# nrf9230_celldsp register map
Vendor: Nordic Semiconductor; Series: nRF92; File version: 1
Registers are 32-bit, read-write, reset 0x0 unless marked. A register's access mark holds for its fields unless they carry their own. Offsets are from the block's base; [hi:lo] are bit positions; {n}, {i} and the like mark numbered series; 'fields as' and 'values as' point back to an identical list.

## GNSSFE — Position Front End 0
Base 0x45028000
Same registers: WIFIBFE 0x45029000, WIFIGNFE 0x4502A000
0x00 TASKS_STARTRX wo — Start receiving rx samples from RF digital
  [0] TASKS_STARTRX
    1=Trigger task
0x04 TASKS_STOPRX wo — Stop receiving rx samples from RF digital
  [0] TASKS_STOPRX
    1=Trigger task
0x08 TASKS_RESET wo — Reset configuration registers to initial state.
  [0] TASKS_RESET
    1=Trigger task
0x0C TASKS_STARTRXTIMED wo — Start receiving rx samples from RF digital when TBC = RXSTART
  [0] TASKS_STARTRXTIMED
    1=Trigger task
0x100 EVENTS_RXSAMPLEREADY — Programmable number of rx samples received from RF digital
  [0] EVENTS_RXSAMPLEREADY
    0=NotGenerated (Event not generated); 1=Generated (Event generated)
0x104 EVENTS_RXSADDRREADY — Rx samples written to programmable RAM buffer address
  [0] EVENTS_RXSADDRREADY
    values as EVENTS_RXSAMPLEREADY.EVENTS_RXSAMPLEREADY
0x108 EVENTS_RX2SADDRREADY — Rx samples written to programmable secondary RAM buffer address
  [0] EVENTS_RX2SADDRREADY
    values as EVENTS_RXSAMPLEREADY.EVENTS_RXSAMPLEREADY
0x10C EVENTS_RXOVERFLOW — Rx fifo overflow event
  [0] EVENTS_RXOVERFLOW
    values as EVENTS_RXSAMPLEREADY.EVENTS_RXSAMPLEREADY
0x110 EVENTS_RXRESYNCOVERFLOW — Rx Resync fifo overflow event
  [0] EVENTS_RXRESYNCOVERFLOW
    values as EVENTS_RXSAMPLEREADY.EVENTS_RXSAMPLEREADY
0x114 EVENTS_RX2SAMPLEREADY — Programmable number of rx samples received to secondary buffer from RF digital
  [0] EVENTS_RX2SAMPLEREADY
    values as EVENTS_RXSAMPLEREADY.EVENTS_RXSAMPLEREADY
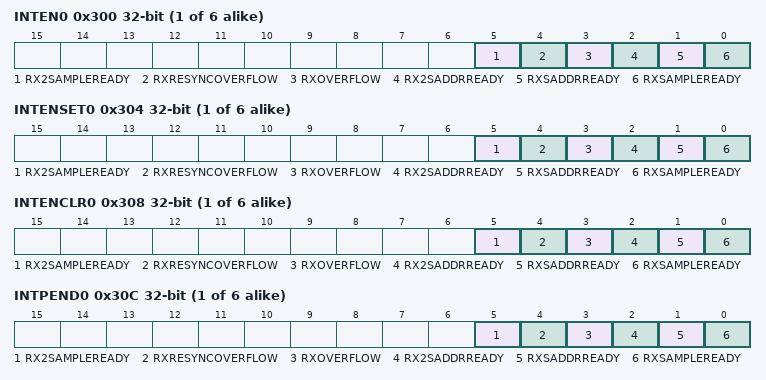
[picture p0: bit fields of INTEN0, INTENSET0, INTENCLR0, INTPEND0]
{0x300+0x10*i} INTEN{i} (i=0..5) — Enable or disable interrupt
  [all] fields
    0=Disabled; 1=Enabled
  [5] RX2SAMPLEREADY — Enable or disable interrupt for event RX2SAMPLEREADY
  [4] RXRESYNCOVERFLOW — Enable or disable interrupt for event RXRESYNCOVERFLOW
  [3] RXOVERFLOW — Enable or disable interrupt for event RXOVERFLOW
  [2] RX2SADDRREADY — Enable or disable interrupt for event RX2SADDRREADY
  [1] RXSADDRREADY — Enable or disable interrupt for event RXSADDRREADY
  [0] RXSAMPLEREADY — Enable or disable interrupt for event RXSAMPLEREADY
{0x304+0x10*i} INTENSET{i} (i=0..5) — Enable interrupt
  [all] fields
    on read: 0=Disabled (Read: Disabled); 1=Enabled (Read: Enabled) | on write: 1=Set (Enable)
  [5] RX2SAMPLEREADY — Write '1' to enable interrupt for event RX2SAMPLEREADY
  [4] RXRESYNCOVERFLOW — Write '1' to enable interrupt for event RXRESYNCOVERFLOW
  [3] RXOVERFLOW — Write '1' to enable interrupt for event RXOVERFLOW
  [2] RX2SADDRREADY — Write '1' to enable interrupt for event RX2SADDRREADY
  [1] RXSADDRREADY — Write '1' to enable interrupt for event RXSADDRREADY
  [0] RXSAMPLEREADY — Write '1' to enable interrupt for event RXSAMPLEREADY
{0x308+0x10*i} INTENCLR{i} (i=0..5) — Disable interrupt
  [all] fields
    on read: 0=Disabled (Read: Disabled); 1=Enabled (Read: Enabled) | on write: 1=Clear (Disable)
  [5] RX2SAMPLEREADY — Write '1' to disable interrupt for event RX2SAMPLEREADY
  [4] RXRESYNCOVERFLOW — Write '1' to disable interrupt for event RXRESYNCOVERFLOW
  [3] RXOVERFLOW — Write '1' to disable interrupt for event RXOVERFLOW
  [2] RX2SADDRREADY — Write '1' to disable interrupt for event RX2SADDRREADY
  [1] RXSADDRREADY — Write '1' to disable interrupt for event RXSADDRREADY
  [0] RXSAMPLEREADY — Write '1' to disable interrupt for event RXSAMPLEREADY
{0x30C+0x10*i} INTPEND{i} ro (i=0..5) — Pending interrupts
  [all] fields
    on read: 0=NotPending (Read: Not pending); 1=Pending (Read: Pending)
  [5] RX2SAMPLEREADY — Read pending status of interrupt for event RX2SAMPLEREADY
  [4] RXRESYNCOVERFLOW — Read pending status of interrupt for event RXRESYNCOVERFLOW
  [3] RXOVERFLOW — Read pending status of interrupt for event RXOVERFLOW
  [2] RX2SADDRREADY — Read pending status of interrupt for event RX2SADDRREADY
  [1] RXSADDRREADY — Read pending status of interrupt for event RXSADDRREADY
  [0] RXSAMPLEREADY — Read pending status of interrupt for event RXSAMPLEREADY
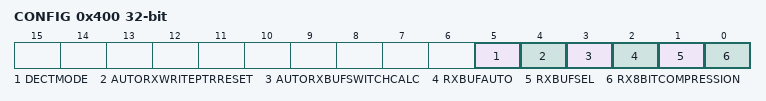
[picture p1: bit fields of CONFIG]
0x400 CONFIG — POSFE configuration register
  [5] DECTMODE — DECT mode selection for interfacing to DECTSYNC HW for non-DECT signal receiving
    0=Disabled (DECT mode disabled); 1=Enabled (DECT mode enabled)
  [4] AUTORXWRITEPTRRESET — Automatic Rx write pointer reset in AHB FSM
    0=Disabled (Autoreset disabled); 1=Enabled (Autoreset enabled)
  [3] AUTORXBUFSWITCHCALC — Automatic Rx buffer switchpoint calculation
    0=Disabled (Autocalculation disabled); 1=Enabled (Autocalculation enabled)
  [2] RXBUFAUTO — Automatic rx buffer switching mode
    0=Disabled (Automatic mode disabled); 1=Enabled (Automatic mode enabled)
  [1] RXBUFSEL — Manual rx buffer switching mode. In automatic mode defines also which buffer will be filled first
    0=Main rx buffer selected; 1=Secondary rx buffer selected
  [0] RX8BITCOMPRESSION — RX output format selector
    0=Sixteen (Each sample, I or Q, in output data is 16 bits); 1=Eight (Each sample, I or Q, in output data is 8 bits)
0x404 TBCINITVALUELO — Lower 32 bits of TimeBaseCounter initialization value
  [31:0] TBCINITLO — TBC Initialization
0x408 TBCINITVALUEHI — Higher 32 bits of TimeBaseCounter initialization value
  [31:0] TBCINITHI — TBC Initialization
0x40C TBCRXENDLO — Lower 32 bits of Rx End time
  [31:0] RXENDLO — TBC count to disable RX
0x410 TBCRXENDHI — Higher 32 bits of Rx End time
  [31:0] RXENDHI — TBC count to disable RX
0x414 RXBUFSWITCHLO — Lower 32 bits of TBC value to switch to another RAM buffer
  [31:0] RX2SWITCHLO — Switch point to secondary Rx buffer
0x418 RXBUFSWITCHHI — Higher 32 bits of TBC value to switch to another RAM buffer
  [31:0] RX2SWITCHI — Switch point to secondary Rx buffer
0x41C RXSAMPLEINTTRIG — Rx sample interrupt trigger value. Number of samples received from RF digital.
  [15:0] RXSAMPLEINTTRIG — Rx sample interrupt trigger
0x420 RXSADDRINTTRIG — Rx sample interrupt trigger value. RAM address where samples written.
  [31:0] RXSADDRINTTRIG — Rx sample interrupt trigger.
0x424 RX2SADDRINTTRIG — Rx 2 sample interrupt trigger value. RAM address where samples written.
  [31:0] RX2SADDRINTTRIG — Rx 2 sample interrupt trigger
0x428 RXDMABASEADDR — Rx write base address to RAM memory
  [31:0] RXDMABASEADDR — Rx buffer base address
0x42C RXDMABUFFERSIZE — Rx RAM buffer size
  [31:0] RXDMABUFFERSIZE — Rx buffer size
0x430 RXDMAWRITEPTR — Rx write pointer to RAM memory
  [31:0] RXDMAWRITEPTR — Rx buffer write pointer
0x434 RX2DMABASEADDR — Rx 2 write base address to RAM memory
  [31:0] RX2DMABASEADDR — Rx buffer 2 base address
0x438 RX2DMABUFFERSIZE — Rx 2 RAM buffer size
  [31:0] RX2DMABUFFERSIZE — Rx buffer 2 size
0x43C RX2DMAWRITEPTR — Rx 2 write pointer to RAM memory
  [31:0] RX2DMAWRITEPTR — Rx buffer 2 write pointer
0x440 PATHSTATUS ro
  [0] RXPATH — RX path status
    0=TaskInactive (Rx task not activated); 1=TaskActive (Rx task ongoing)
0x444 RX2SAMPLEINTTRIG — Rx secondary buffer sample interrupt trigger value. Number of samples received from RF digital.
  [15:0] RX2SAMPLEINTTRIG — Rx 2 sample interrupt trigger
0x448 RXSAMPLECOUNTER ro — Rx sample counter value
  [15:0] RXSAMPLECNTR
0x44C RXSLOTSIZELO — Lower 32 bits of Rx slot size in automatic buffer switching
  [31:0] RXSLOTLO — Rx slot size
0x450 RXSLOTSIZEHI — Higher 32 bits of Rx slot size in automatic buffer switching
  [31:0] RXSLOTHI — Rx slot size
0x454 RXSTARTLO — Lower 32 bits of Rx start time in timed rx mode
  [31:0] RXSTARTLO — TBC count to start Rx
0x458 RXSTARTHI — Higher 32 bits of Rx start time in timed rx mode
  [31:0] RXSTARTHI — TBC count to start Rx
0x45C RXSTOPLO — Lower 32 bits of Rx stop time in timed rx mode
  [31:0] RXSTOPLO — TBC count to stop Rx
0x460 RXSTOPHI — Higher 32 bits of Rx stop time in timed rx mode
  [31:0] RXSTOPHI — TBC count to stop Rx
0x464 RXROUNDCONSTPOS reset 0xFF — Rounding constant for 8bit output format
  [15:0] RXROUNDCONSTPOS — Constant for positive input values
0x468 RXROUNDCONSTNEG — Rounding constant for 8bit output format
  [15:0] RXROUNDCONSTNEG — Constant for negative input values
0x46C RXBUSERROR — AHB bus error indication sticky bit. Check also ReSynch overflow IRQ.
  [15:0] RXBUSERROR — Write 0 to clear.
0x470 TBCINCREMENT — TBC increment step selector
  [1:0] TBCINCREMENT — 0: step=32, 1: step=16, 2: step=1, 3: step=64
0x474 RXMAINSAMPLECNTR ro — Total number of transferred Rx samples
0x478 RXOVERFLOWSAMPLES ro — Number of overflow samples in Rx path
0x47C DECTSTARTLO — Lower 32 bits of DectSync start time
  [31:0] DECTSTARTLO — TBC count to start DectSync
0x480 DECTSTARTHI — Higher 32 bits of DectSync start time
  [31:0] DECTSTARTHI — TBC count to start DectSync
0x484 DECTSTOPLO — Lower 32 bits of DectSync stop time
  [31:0] DECTSTOPLO — TBC count to stop DectSync
0x488 DECTSTOPHI — Higher 32 bits of DectSync stop time
  [31:0] DECTSTOPHI — TBC count to stop DectSync
0x48C DECTSYNCSAMPLECNTR ro — Number of transferred samples in DectSync mode
  [31:0] DECTSYNCSAMPLECNTR — DectSync sample counter value
